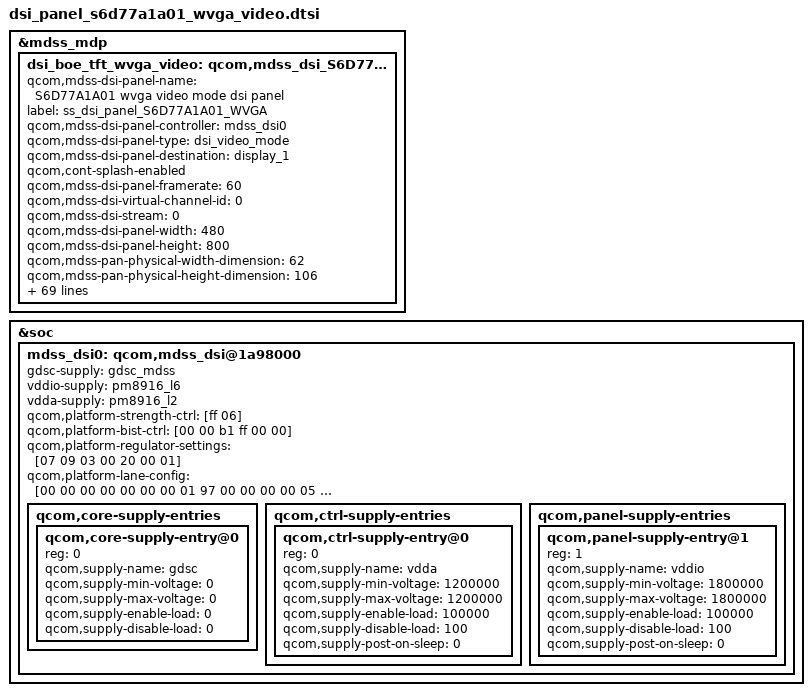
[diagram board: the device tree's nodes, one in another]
/* Copyright (c) 2013-14, Samsung Electronics Corporation. All rights reserved.
 *
 * This program is free software; you can redistribute it and/or modify
 * it under the terms of the GNU General Public License version 2 and
 * only version 2 as published by the Free Software Foundation.
 *
 * This program is distributed in the hope that it will be useful,
 * but WITHOUT ANY WARRANTY; without even the implied warranty of
 * MERCHANTABILITY or FITNESS FOR A PARTICULAR PURPOSE.  See the
 * GNU General Public License for more details.
 */

/*---------------------------------------------------------------------------
 * This file is autogenerated file using gcdb parser. Please do not edit it.
 * Update input XML file to add a new entry or update variable in this file
 * VERSION = "1.0"
 *---------------------------------------------------------------------------*/
&mdss_mdp {
	dsi_boe_tft_wvga_video: qcom,mdss_dsi_S6D77A1A01_wvga_video {
		qcom,mdss-dsi-panel-name = "S6D77A1A01 wvga video mode dsi panel";
		label = "ss_dsi_panel_S6D77A1A01_WVGA";
		qcom,mdss-dsi-panel-controller = <&mdss_dsi0>;
		qcom,mdss-dsi-panel-type = "dsi_video_mode";
		qcom,mdss-dsi-panel-destination = "display_1";
		qcom,cont-splash-enabled;
		qcom,mdss-dsi-panel-framerate = <60>;
		qcom,mdss-dsi-virtual-channel-id = <0>;
		qcom,mdss-dsi-stream = <0>;
		qcom,mdss-dsi-panel-width = <480>;
		qcom,mdss-dsi-panel-height = <800>;
		qcom,mdss-pan-physical-width-dimension = <62>; /* <Width> real size of panel in mm */
		qcom,mdss-pan-physical-height-dimension = <106>; /*<Height> real size of panel in mm */
		qcom,mdss-dsi-lp11-init;
		qcom,mdss-dsi-init-delay-us = <100>;
		qcom,mdss-dsi-h-front-porch = <84>;
		qcom,mdss-dsi-h-back-porch = <90>;
		qcom,mdss-dsi-h-pulse-width = <40>;
		qcom,mdss-dsi-h-sync-skew = <0>;
		qcom,mdss-dsi-v-back-porch = <12>;
		qcom,mdss-dsi-v-front-porch = <16>;
		qcom,mdss-dsi-v-pulse-width = <4>;
		qcom,mdss-dsi-h-left-border = <0>;
		qcom,mdss-dsi-h-right-border = <0>;
		qcom,mdss-dsi-v-top-border = <0>;
		qcom,mdss-dsi-v-bottom-border = <0>;
		qcom,mdss-dsi-bpp = <24>;
		qcom,mdss-dsi-color-order = <0>;
		qcom,mdss-dsi-underflow-color = <0xff>;
		qcom,mdss-dsi-border-color = <0>;
		qcom,mdss-dsi-dma-trigger = "trigger_sw";
		qcom,mdss-dsi-mdp-trigger = "none";
		qcom,mdss-dsi-bl-min-level = <1>;
		qcom,mdss-dsi-bl-max-level = <255>;
		qcom,mdss-dsi-bl-pmic-control-type = "bl_ctrl_dcs";
		qcom,mdss-dsi-lane-0-state;
		qcom,mdss-dsi-lane-1-state;
		qcom,mdss-dsi-bllp-eof-power-mode;
		qcom,mdss-dsi-bllp-power-mode;
		qcom,mdss-dsi-traffic-mode = "burst_mode";
		qcom,mdss-force-clk-lane-hs = <0>;
		qcom,mdss-dsi-reset-sequence = <1 20>, <0 1>, <1 20>;
		qcom,mdss-dsi-h-sync-pulse = <0>;
		qcom,mdss-dsi-panel-timings = [79 1A 10 00 3E 40 16 1C 0F 03 04 00];
		qcom,mdss-dsi-t-clk-pre = <0x15>;
		qcom,mdss-dsi-t-clk-post = <0x04>;
		qcom,mdss-dsi-on-command = [
					39 01 00 00 00 00 03 F0 5A 5A
					39 01 00 00 00 00 03 FC A5 A5

					39 01 00 00 00 00 02 B3 01
					39 01 00 00 00 00 02 B5 10
					39 01 00 00 00 00 04 BC 01 29 51

					39 01 00 00 00 00 03 E3 24 2C

					39 01 00 00 00 00 01 21

					39 01 00 00 00 00 08 F2 11 04 08 10 10 82 54
					39 01 00 00 00 00 06 F3 91 00 00 00 10
					39 01 00 00 00 00 2C F4 01 02 23 24 25 25 26 26 29 29 2C 2B 2C 07 08 05 04 04 01 01 22 0A 17 0F 11 23 0D 0A 0B 02 19 13 1E 1F 23 20 05 16 1A 16 1E 24 1E
					39 01 00 00 00 00 1D F5 28 28 B9 21 35 55 36 0A 00 39 00 00 0B 4B C4 CB 4B 12 12 1A 00 10 E0 E2 0E 34 34 03
					39 01 00 00 00 00 12 FE 00 02 01 39 60 40 21 00 4B 00 80 00 F0 00 00 00 02

                    /*<Initializing Sequence (2)>*/
					39 01 00 00 00 00 0B EE 00 A8 00 A0 00 00 00 00 00 00
					39 01 00 00 00 00 16 EF 23 01 00 00 2A 49 08 27 21 40 10 28 02 21 21 03 03 40 00 08 00
					39 01 00 00 00 00 1F F7 02 1B 0D 0D 09 09 0C 0C 08 08 04 06 1A 02 02 02 1B 0F 0F 0B 0B 0E 0E 0A 0A 05 07 1A 02 02
					39 01 00 00 00 00 07 F6 63 25 15 00 00 2A
					39 01 00 00 00 00 02 36 10

					/* gamma setting*/
					39 01 00 00 00 00 12 FA 0C 36 11 17 0E 14 19 18 1A 21 23 22 22 21 22 22 29
					39 01 00 00 00 00 12 FB 0C 36 12 17 0F 14 19 18 1A 21 24 22 23 21 22 22 29
					/* gamma setting*/

					/*<power setting sequence(1-2)>*/
					39 01 00 00 00 00 03 FC 5A 5A

					/* < Display on Sequence> */
					05 01 00 00 78 00 02 11 00
					05 01 00 00 0A 00 02 29 00
					39 01 00 00 00 00 06 C0 57 01 F9 40 21              //pwm chage to 30KHz

					39 01 00 00 00 00 02 55 01
					39 01 00 00 00 00 02 53 24
					];
		qcom,mdss-dsi-on-command-state = "dsi_lp_mode";
		qcom,mdss-dsi-off-command-state = "dsi_hs_mode";
		qcom,mdss-dsi-off-command = [39 01 00 10  00 02 28 00
					39 01 00 00 46 00 02 10 00];
		samsung,tft-common-support;
		samsung,panel-vendor = "BOE";
		samsung,mdss-dsi-bl-scale-low-level = <8>;
		samsung,mdss-dsi-bl-scale-dim-level = <8>;
		samsung,mdss-dsi-bl-scale-default-level = <89>;
		samsung,mdss-dsi-bl-scale-max-level = <188>;
		samsung,mdss-dsi-bl-pms-low-level = <7>;
		samsung,mdss-dsi-bl-pms-dim-level = <7>;
		samsung,mdss-dsi-bl-pms-default-level = <158>;
		samsung,mdss-dsi-bl-pms-max-level = <255>;
/*
 * ************************************************************************************************************************************
 *
 *
 *			Below  parameters are samsung dependent thigs
 *
 *
 * ************************************************************************************************************************************
 */ 
		samsung,packet_size_tx_cmds_revA = [
			37 01 00 00 00 00 02 07 00
		];
		/*
		 * First parameters can be changed
		 * by function of samsung_nv_read()
		 * because of that means offset of
		 * read position
		 */		
		samsung,reg_read_pos_tx_cmds_revA = [
			15 01 00 00 00 00 02 B0 00
		];
		samsung,manufacture_id0_rx_cmds_revA = [06 01 00 00 00 00 01 da 03 00];
		samsung,manufacture_id1_rx_cmds_revA = [06 01 00 00 00 00 01 db 03 00];
		samsung,manufacture_id2_rx_cmds_revA = [06 01 00 00 00 00 01 dc 03 00];
/*
		* Command sets for CABC control
*/
		samsung,tft_pwm_tx_cmds_revA=[
			39 01 00 00 00 00 02 51 FF/*First command should be PWM duty change command*/
		];
		samsung,cabc_on_tx_cmds_revA = [
			39 01 00 00 00 00 02 55 01
		];
		samsung,cabc_off_tx_cmds_revA = [
			39 01 00 00 00 00 02 55 00
		];
		/*
		* ************************************************************************************************************************
		* Scaled level to index mappings
		* ************************************************************************************************************************
		*/
		//for j1_vzw
	samsung,scaled_level_map_table_revA = <
		/*<idx>	  <from>  <till> <scaled_level> */
			0		0		7		5
			1		8		9		6
			2		10		12		7
			3		13		14		8
			4		15		17		9
			5		18		19		10
			6		20		22		11
			7		23		24		12
			8		25		27		13
			9		28		29		14
			10		30		32		15
			11		33		34		16
			12		35		37		17
			13		38		39		18
			14		40		42		29
			15		43		44		20
			16		45		47		21
			17		48		49		22
			18		50		52		23
			19		53		54		24
			20		55		57		25
			21		58		59		26
			22		60		62		27
			23		63		64		28
			24		65		67		29
			25		68		70		30
			26		71		72		31
			27		73		75		32
			28		76		77		33
			29		78		80		34
			30		81		82		35
			31		83		85		36
			32		86		87		38
			33		88		90		40
			34		91		92		42
			35		93		95		44
			36		96		97		46
			37		98		100		48
			38		101		102		50
			39		103		105		52
			40		106		107		54
			41		108		110		56
			42		111		112		58
			43		113		115		60
			44		116		117		62
			45		118		120		64
			46		121		122		66
			47		123		125		68
			48		126		127		70
			49		128		130		72
			50		131		133		74
			51		134		135		76
			52		136		138		78
			53		139		140		80
			54		141		143		82
			55		144		145		84
			56		146		148		86
			57		149		150		88
			58		151		153		90
			59		154		155		92
			60		156		158		94
			61		159		160		96
			62		161		163		98
			63		164		165		100
			64		166		168		102
			65		169		170		104
			66		171		173		106
			67		174		175		108
			68		176		178		110
			69		179		180		112
			70		181		183		114
			71		184		185		116
			72		186		188		118
			72		189		190		120
			74		191		193		122
			75		194		196		124
			76		197		198		126
			77		199		201		128
			78		202		203		130
			79		204		206		132
			80		207		208		134
			81		209		211		136
			82		212		213		138
			83		214		216		140
			84		217		218		142
			85		219		221		144
			86		222		223		147
			87		224		226		150
			88		227		228		153
			89		229		231		156
			90		232		233		159
			91		234		236		162
			92		237		238		165
			93		239		241		168
			94		242		243		172
			95		244		246		176
			96		247		248		180
			97		249		251		184
			98		252		253		188
			99		254		255		192
		>;
	};
};
&soc {
	mdss_dsi0: qcom,mdss_dsi@1a98000 {
		gdsc-supply = <&gdsc_mdss>;
		vddio-supply = <&pm8916_l6>;
		vdda-supply = <&pm8916_l2>;
		qcom,platform-strength-ctrl = [ff 06];
		qcom,platform-bist-ctrl = [00 00 b1 ff 00 00];
		qcom,platform-regulator-settings = [07 09 03 00 20 00 01];
		qcom,platform-lane-config = [00 00 00 00 00 00 00 01 97
			00 00 00 00 05 00 00 01 97
			00 00 00 00 0a 00 00 01 97
			00 00 00 00 0f 00 00 01 97
			00 c0 00 00 00 00 00 01 bb];
		qcom,core-supply-entries {
			#address-cells = <1>;
			#size-cells = <0>;

			qcom,core-supply-entry@0 {
				reg = <0>;
				qcom,supply-name = "gdsc";
				qcom,supply-min-voltage = <0>;
				qcom,supply-max-voltage = <0>;
				qcom,supply-enable-load = <0>;
				qcom,supply-disable-load = <0>;
			};
		};
		qcom,ctrl-supply-entries {
			#address-cells = <1>;
			#size-cells = <0>;

			qcom,ctrl-supply-entry@0 {
				reg = <0>;
				qcom,supply-name = "vdda";
				qcom,supply-min-voltage = <1200000>;
				qcom,supply-max-voltage = <1200000>;
				qcom,supply-enable-load = <100000>;
				qcom,supply-disable-load = <100>;
				qcom,supply-post-on-sleep = <0>;
			};
		};
		qcom,panel-supply-entries {
			#address-cells = <1>;
			#size-cells = <0>;

			qcom,panel-supply-entry@1 {
				reg = <1>;
				qcom,supply-name = "vddio";
				qcom,supply-min-voltage = <1800000>;
				qcom,supply-max-voltage = <1800000>;
				qcom,supply-enable-load = <100000>;
				qcom,supply-disable-load = <100>;
				qcom,supply-post-on-sleep = <0>;
			};
		};
	};
};

